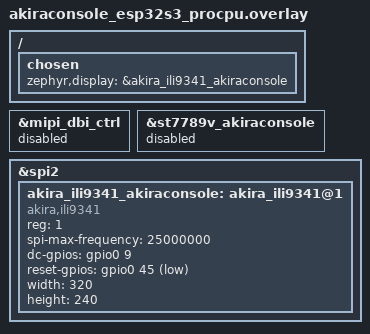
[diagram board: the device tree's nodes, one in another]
/*
 * ILI9341 overlay for AkiraConsole ESP32-S3.
 *
 * Applied by the akira-display-ili9341 snippet (west build -S akira-display-ili9341).
 *
 * Overrides the default zephyr,display (ST7789V) with the akira,ili9341 node
 * and explicitly disables the ST7789V and MIPI-DBI nodes so no stray driver
 * can bind to them.
 *
 * Hardware: DC=GPIO9, RST=GPIO45, CS=GPIO10 (SPI2 cs-gpios[1])
 */

#include <zephyr/dt-bindings/gpio/gpio.h>

/* Override chosen display */
/ {
	chosen {
		zephyr,display = &akira_ili9341_akiraconsole;
	};
};

/*
 * Explicitly disable the ST7789V node and its MIPI-DBI parent.
 * Prevents CONFIG_DT_HAS_SITRONIX_ST7789V_ENABLED and stops any MIPI-DBI
 * driver from claiming the DC or RST pins.
 */
&mipi_dbi_ctrl {
	status = "disabled";
};

&st7789v_akiraconsole {
	status = "disabled";
};

/* ILI9341 direct-SPI node — CS is cs-gpios[1] = GPIO10 */
&spi2 {
	akira_ili9341_akiraconsole: akira_ili9341@1 {
		compatible        = "akira,ili9341";
		reg               = <1>;                           /* cs-gpios[1] = GPIO10 */
		spi-max-frequency = <25000000>;                    /* 25 MHz               */
		dc-gpios          = <&gpio0 9  GPIO_ACTIVE_HIGH>;  /* TFT_DC  = GPIO9      */
		reset-gpios       = <&gpio0 45 GPIO_ACTIVE_LOW>;   /* TFT_RST = GPIO45     */
		width             = <320>;
		height            = <240>;
		status            = "okay";
	};
};
